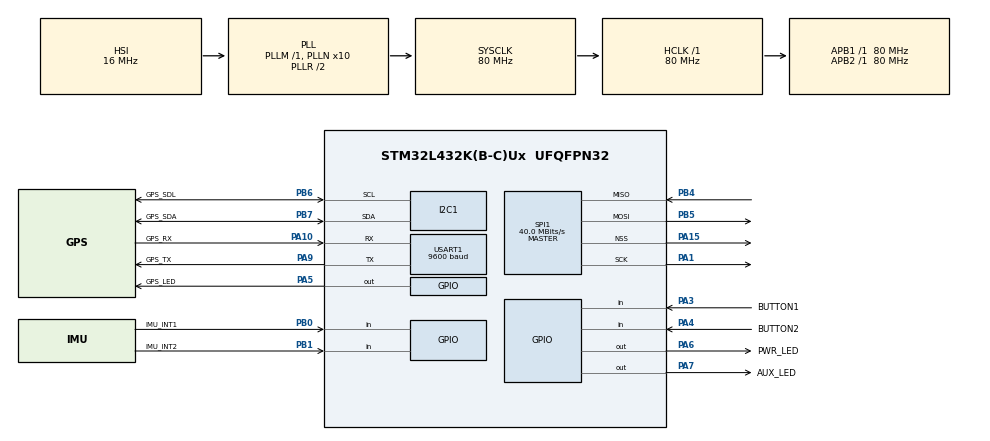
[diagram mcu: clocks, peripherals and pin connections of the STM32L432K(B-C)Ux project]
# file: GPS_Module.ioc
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Dma.Request0=USART1_RX
Dma.Request1=USART1_TX
Dma.USART1_RX.0.Direction=DMA_PERIPH_TO_MEMORY
Dma.USART1_RX.0.Instance=DMA1_Channel5
Dma.USART1_RX.0.MemDataAlignment=DMA_MDATAALIGN_BYTE
Dma.USART1_RX.0.MemInc=DMA_MINC_ENABLE
Dma.USART1_RX.0.Mode=DMA_NORMAL
Dma.USART1_RX.0.PeriphDataAlignment=DMA_PDATAALIGN_BYTE
Dma.USART1_RX.0.PeriphInc=DMA_PINC_DISABLE
Dma.USART1_RX.0.Priority=DMA_PRIORITY_LOW
Dma.USART1_TX.1.Direction=DMA_MEMORY_TO_PERIPH
Dma.USART1_TX.1.Instance=DMA1_Channel4
Dma.USART1_TX.1.MemDataAlignment=DMA_MDATAALIGN_BYTE
Dma.USART1_TX.1.MemInc=DMA_MINC_ENABLE
Dma.USART1_TX.1.Mode=DMA_NORMAL
Dma.USART1_TX.1.PeriphDataAlignment=DMA_PDATAALIGN_BYTE
Dma.USART1_TX.1.PeriphInc=DMA_PINC_DISABLE
Dma.USART1_TX.1.Priority=DMA_PRIORITY_LOW
I2C1.Timing=0x10909CEC
Mcu.Family=STM32L4
Mcu.Name=STM32L432K(B-C)Ux
Mcu.Package=UFQFPN32
NVIC.DMA1_Channel4_IRQn=true\:0\:0\:false\:false\:true\:false\:true
NVIC.DMA1_Channel5_IRQn=true\:0\:0\:false\:false\:true\:false\:true
NVIC.PriorityGroup=NVIC_PRIORITYGROUP_4
NVIC.USART1_IRQn=true\:0\:0\:false\:false\:true\:true\:true
PA1.Mode=Full_Duplex_Master
PA1.Signal=SPI1_SCK
PA10.GPIO_Label=GPS_RX
PA10.Mode=Asynchronous
PA10.Signal=USART1_RX
PA13\ (JTMS-SWDIO).Mode=Trace_Asynchronous_SW
PA13\ (JTMS-SWDIO).Signal=SYS_JTMS-SWDIO
PA14\ (JTCK-SWCLK).Mode=Trace_Asynchronous_SW
PA14\ (JTCK-SWCLK).Signal=SYS_JTCK-SWCLK
PA15\ (JTDI).Mode=NSS_Signal_Hard_Output
PA15\ (JTDI).Signal=SPI1_NSS
PA3.GPIO_Label=BUTTON1
PA3.Signal=GPIO_Input
PA4.GPIO_Label=BUTTON2
PA4.Signal=GPIO_Input
PA5.GPIO_Label=GPS_LED
PA5.Signal=GPIO_Output
PA6.GPIO_Label=PWR_LED
PA6.Signal=GPIO_Output
PA7.GPIO_Label=AUX_LED
PA7.Signal=GPIO_Output
PA9.GPIO_Label=GPS_TX
PA9.Mode=Asynchronous
PA9.Signal=USART1_TX
PB0.GPIO_Label=IMU_INT1
PB0.Signal=GPIO_Input
PB1.GPIO_Label=IMU_INT2
PB1.Signal=GPIO_Input
PB3\ (JTDO-TRACESWO).Mode=Trace_Asynchronous_SW
PB3\ (JTDO-TRACESWO).Signal=SYS_JTDO-SWO
PB4\ (NJTRST).Mode=Full_Duplex_Master
PB4\ (NJTRST).Signal=SPI1_MISO
PB5.Mode=Full_Duplex_Master
PB5.Signal=SPI1_MOSI
PB6.GPIO_Label=GPS_SDL
PB6.Mode=I2C
PB6.Signal=I2C1_SCL
PB7.GPIO_Label=GPS_SDA
PB7.Mode=I2C
PB7.Signal=I2C1_SDA
PC14-OSC32_IN\ (PC14).Mode=LSE-External-Oscillator
PC14-OSC32_IN\ (PC14).Signal=RCC_OSC32_IN
PC15-OSC32_OUT\ (PC15).Mode=LSE-External-Oscillator
PC15-OSC32_OUT\ (PC15).Signal=RCC_OSC32_OUT
ProjectManager.HeapSize=0x200
ProjectManager.StackSize=0x400
ProjectManager.TargetToolchain=Makefile
RCC.ADCCLockSelection=RCC_ADCCLKSOURCE_SYSCLK
RCC.ADCFreq_Value=80000000
RCC.AHBFreq_Value=80000000
RCC.APB1Freq_Value=80000000
RCC.APB1TimFreq_Value=80000000
RCC.APB2Freq_Value=80000000
RCC.APB2TimFreq_Value=80000000
RCC.CortexFreq_Value=80000000
RCC.HCLKFreq_Value=80000000
RCC.HSE_VALUE=8000000
RCC.HSI48_VALUE=48000000
RCC.HSI_VALUE=16000000
RCC.MSI_VALUE=4000000
RCC.PLLN=10
RCC.PLLSAI1N=16
RCC.PLLSourceVirtual=RCC_PLLSOURCE_HSI
RCC.SYSCLKFreq_VALUE=80000000
RCC.SYSCLKSource=RCC_SYSCLKSOURCE_PLLCLK
RCC.USBFreq_Value=128000000
RCC.VCOOutputFreq_Value=160000000
SPI1.BaudRatePrescaler=SPI_BAUDRATEPRESCALER_2
SPI1.CalculateBaudRate=40.0 MBits/s
SPI1.Direction=SPI_DIRECTION_2LINES
SPI1.Mode=SPI_MODE_MASTER
SPI1.VirtualNSS=VM_NSSHARD
SPI1.VirtualType=VM_MASTER
USART1.BaudRate=9600
USART1.VirtualMode-Asynchronous=VM_ASYNC
board=custom

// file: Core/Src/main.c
/* USER CODE BEGIN Header */
/**
  ******************************************************************************
  * @file           : main.c
  * @brief          : Main program body
  ******************************************************************************
  * @attention
  *
  * <h2><center>&copy; Copyright (c) 2021 STMicroelectronics.
  * All rights reserved.</center></h2>
  *
  * This software component is licensed by ST under BSD 3-Clause license,
  * the "License"; You may not use this file except in compliance with the
  * License. You may obtain a copy of the License at:
  *                        opensource.org/licenses/BSD-3-Clause
  *
  ******************************************************************************
  */
/* USER CODE END Header */
#include "main.h"
#include "dma.h"
#include "i2c.h"
#include "spi.h"
#include "usart.h"
#include "gpio.h"

/* USER CODE BEGIN Includes */
#include <stdio.h>
#include "SEGGER_RTT.h"
/* USER CODE END Includes */

/* USER CODE BEGIN PV */
char buff[512];
/* USER CODE END PV */

void SystemClock_Config(void);

int main(void)
{

  /* MCU Configuration--------------------------------------------------------*/

  /* Reset of all peripherals, Initializes the Flash interface and the Systick. */
  HAL_Init();

  /* Configure the system clock */
  SystemClock_Config();

  /* Initialize all configured peripherals */
  MX_GPIO_Init();
  MX_DMA_Init();
  MX_I2C1_Init();
  MX_USART1_UART_Init();
  MX_SPI1_Init();
  /* USER CODE BEGIN 2 */
  SEGGER_RTT_ConfigUpBuffer(0,NULL,NULL,0, SEGGER_RTT_MODE_BLOCK_IF_FIFO_FULL);
  HAL_GPIO_WritePin(PWR_LED_GPIO_Port,PWR_LED_Pin,1);
  HAL_GPIO_WritePin(PWR_LED_GPIO_Port,PWR_LED_Pin,0);
  HAL_UART_Receive_DMA(&huart1, buff, sizeof(buff));
  /* USER CODE END 2 */

  /* Infinite loop */
  while (1)
  {

  }
}

void SystemClock_Config(void)
{
  RCC_OscInitTypeDef RCC_OscInitStruct = {0};
  RCC_ClkInitTypeDef RCC_ClkInitStruct = {0};
  RCC_PeriphCLKInitTypeDef PeriphClkInit = {0};

  /** Initializes the RCC Oscillators according to the specified parameters
  * in the RCC_OscInitTypeDef structure.
  */
  RCC_OscInitStruct.OscillatorType = RCC_OSCILLATORTYPE_HSI;
  RCC_OscInitStruct.HSIState = RCC_HSI_ON;
  RCC_OscInitStruct.HSICalibrationValue = RCC_HSICALIBRATION_DEFAULT;
  RCC_OscInitStruct.PLL.PLLState = RCC_PLL_ON;
  RCC_OscInitStruct.PLL.PLLSource = RCC_PLLSOURCE_HSI;
  RCC_OscInitStruct.PLL.PLLM = 1;
  RCC_OscInitStruct.PLL.PLLN = 10;
  RCC_OscInitStruct.PLL.PLLP = RCC_PLLP_DIV7;
  RCC_OscInitStruct.PLL.PLLQ = RCC_PLLQ_DIV2;
  RCC_OscInitStruct.PLL.PLLR = RCC_PLLR_DIV2;
  if (HAL_RCC_OscConfig(&RCC_OscInitStruct) != HAL_OK)
  {
    Error_Handler();
  }
  /** Initializes the CPU, AHB and APB buses clocks
  */
  RCC_ClkInitStruct.ClockType = RCC_CLOCKTYPE_HCLK|RCC_CLOCKTYPE_SYSCLK
                              |RCC_CLOCKTYPE_PCLK1|RCC_CLOCKTYPE_PCLK2;
  RCC_ClkInitStruct.SYSCLKSource = RCC_SYSCLKSOURCE_PLLCLK;
  RCC_ClkInitStruct.AHBCLKDivider = RCC_SYSCLK_DIV1;
  RCC_ClkInitStruct.APB1CLKDivider = RCC_HCLK_DIV1;
  RCC_ClkInitStruct.APB2CLKDivider = RCC_HCLK_DIV1;

  if (HAL_RCC_ClockConfig(&RCC_ClkInitStruct, FLASH_LATENCY_4) != HAL_OK)
  {
    Error_Handler();
  }
  PeriphClkInit.PeriphClockSelection = RCC_PERIPHCLK_USART1|RCC_PERIPHCLK_I2C1;
  PeriphClkInit.Usart1ClockSelection = RCC_USART1CLKSOURCE_PCLK2;
  PeriphClkInit.I2c1ClockSelection = RCC_I2C1CLKSOURCE_PCLK1;
  if (HAL_RCCEx_PeriphCLKConfig(&PeriphClkInit) != HAL_OK)
  {
    Error_Handler();
  }
  /** Configure the main internal regulator output voltage
  */
  if (HAL_PWREx_ControlVoltageScaling(PWR_REGULATOR_VOLTAGE_SCALE1) != HAL_OK)
  {
    Error_Handler();
  }
}

void Error_Handler(void)
{
  __disable_irq();
  while (1)
  {
  }
}

/************************ (C) COPYRIGHT STMicroelectronics *****END OF FILE****/
